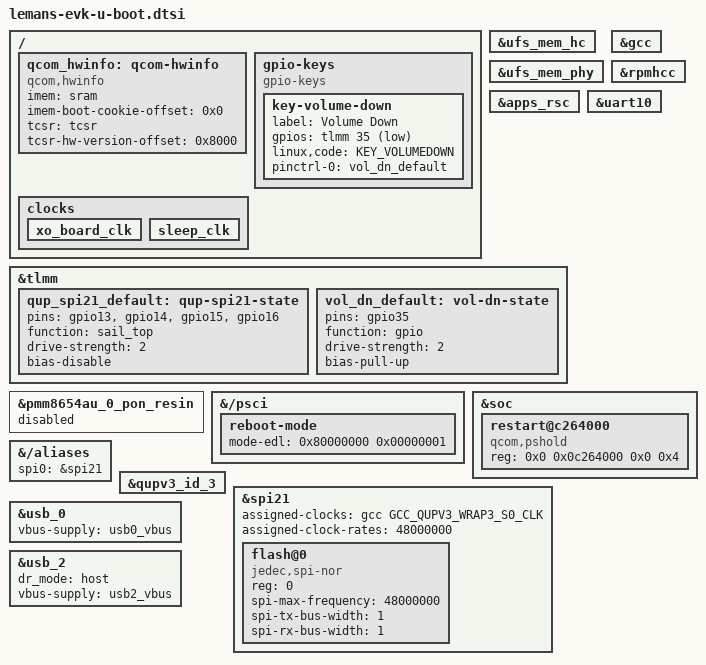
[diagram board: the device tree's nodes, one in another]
// SPDX-License-Identifier: BSD-3-Clause
/*
 * Copyright (c) Qualcomm Technologies, Inc. and/or its subsidiaries.
 */

/ {
	/* IMEM boot cookie + TCSR HW version offsets */
	qcom_hwinfo: qcom-hwinfo {
		compatible = "qcom,hwinfo";

		imem = <&sram>;
		imem-boot-cookie-offset = <0x0>;

		tcsr = <&tcsr>;
		tcsr-hw-version-offset = <0x8000>;
	};

	/* Volume Down is on TLMM GPIO 35, not on the PMIC RESIN input. */
	gpio-keys {
		compatible = "gpio-keys";

		key-volume-down {
			label = "Volume Down";
			gpios = <&tlmm 35 GPIO_ACTIVE_LOW>;
			linux,code = <KEY_VOLUMEDOWN>;
			pinctrl-names = "default";
			pinctrl-0 = <&vol_dn_default>;
		};
	};

	clocks {
		/* Fixed clocks needed by GCC */
		xo_board_clk {
			bootph-all;
		};

		sleep_clk {
			bootph-all;
		};
	};
};

&ufs_mem_hc {
	bootph-all; /* Enable UFS for SPL */
};

&ufs_mem_phy {
	bootph-all;
};

&gcc {
	bootph-all;
};

/* RPMH clock controller - required by GCC */
&rpmhcc {
	bootph-all;
};

/* Apps RSC - parent of rpmhcc and rpmhpd */
&apps_rsc {
	bootph-all;
};

/* UART10 - console serial port */
&uart10 {
	bootph-all;
};

&tlmm {
	bootph-all;   /* Make TLMM GPIO controller available in SPL */

	qup_spi21_default: qup-spi21-state {
		pins = "gpio13", "gpio14", "gpio15", "gpio16";
		function = "sail_top";
		drive-strength = <2>;
		bias-disable;
	};

	vol_dn_default: vol-dn-state {
		pins = "gpio35";
		function = "gpio";
		drive-strength = <2>;
		bias-pull-up;
	};
};

/* pmm8654au has no RESIN input (PAR1 HAS_KPD_RESIN=0): never reports a press. */
&pmm8654au_0_pon_resin {
	status = "disabled";
};

/* Enter Qualcomm EDL/download mode via "reset -edl". */
&{/psci} {
	reboot-mode {
		mode-edl = <0x80000000 0x00000001>;
	};
};

&soc {
	restart@c264000 {
		compatible = "qcom,pshold";
		reg = <0x0 0x0c264000 0x0 0x4>;
		bootph-all;
	};
};

&{/aliases} {
	spi0 = &spi21;
};

&qupv3_id_3 {
	bootph-all;
};

&spi21 {
	assigned-clocks = <&gcc GCC_QUPV3_WRAP3_S0_CLK>;
	assigned-clock-rates = <48000000>;

	flash@0 {
		compatible = "jedec,spi-nor";
		reg = <0>;
		spi-max-frequency = <48000000>;
		spi-tx-bus-width = <1>;
		spi-rx-bus-width = <1>;
	};
};

/*
 * usb_0 (USB0 Type-C) is left in its default mode; only describe its VBUS
 * regulator (GPIO 2 on the TCA9538 expander on i2c18), since the host driver
 * only looks for vbus-supply on the controller node.
 */
&usb_0 {
	vbus-supply = <&usb0_vbus>;
};

/*
 * Run usb_2 (micro-USB) as a USB host so a pendrive can be used to boot. U-Boot
 * has no USB role-switch support, so the dwc3 glue only binds the host driver
 * when dr_mode is explicitly "host". The host driver only looks for vbus-supply
 * on the controller node, so point it at the board's USB2 VBUS regulator.
 */
&usb_2 {
	dr_mode = "host";
	vbus-supply = <&usb2_vbus>;
};
